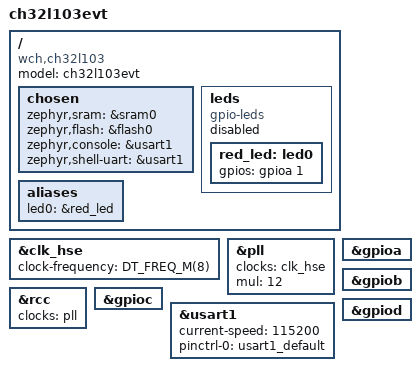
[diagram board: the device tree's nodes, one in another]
/*
 * Copyright (c) 2024 Michael Hope <michaelh@juju.nz>
 * Copyright (c) 2025 Paul Wedeck
 * SPDX-License-Identifier: Apache-2.0
 */

/dts-v1/;

#include <wch/ch32l103/ch32l103c8t.dtsi>
#include "ch32l103evt-pinctrl.dtsi"

#include <zephyr/dt-bindings/gpio/gpio.h>

/ {
	model = "ch32l103evt";
	compatible = "wch,ch32l103";

	chosen {
		zephyr,sram = &sram0;
		zephyr,flash = &flash0;
		zephyr,console = &usart1;
		zephyr,shell-uart = &usart1;
	};

	leds {
		compatible = "gpio-leds";

		/*
		 * Please connect the unconnected LED on the WCH CH32L103EVT
		 * board to a suitable GPIO pin (like PA1) and then change
		 * this status to "okay".
		 */
		status = "disabled";

		red_led: led0 {
			gpios = <&gpioa 1 GPIO_ACTIVE_HIGH>;
		};
	};

	aliases {
		led0 = &red_led;
	};
};

&clk_hse {
	clock-frequency = <DT_FREQ_M(8)>;
	status = "okay";
};

&pll {
	clocks = <&clk_hse>;
	mul = <12>;
	status = "okay";
};

&rcc {
	clocks = <&pll>;
};

&gpioa {
	status = "okay";
};

&gpiob {
	status = "okay";
};

&gpioc {
	status = "okay";
};

&gpiod {
	status = "okay";
};

&usart1 {
	status = "okay";
	current-speed = <115200>;
	pinctrl-0 = <&usart1_default>;
	pinctrl-names = "default";
};
